# ATSAMA5D27 register map
Vendor: Microchip Technology Inc.; File version: 1.0
CPU: CA5 r0p1, little endian, no MPU, no FPU, 4 interrupt priority bits
Address unit: 32 bits
Registers are 32-bit, read-write, reset 0x0 unless marked. A register's access mark holds for its fields unless they carry their own. Offsets are from the block's base; [hi:lo] are bit positions; {n}, {i} and the like mark numbered series.

## SHDWC — Shutdown Controller
Base 0xF8048010
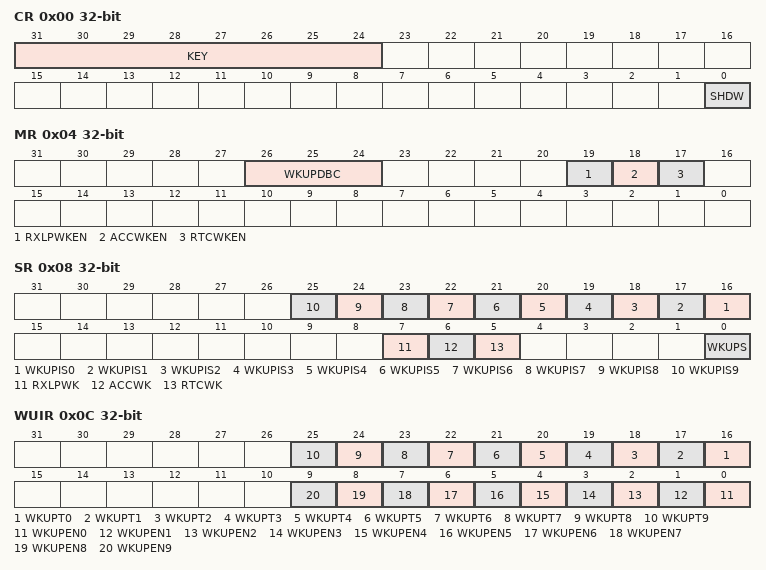
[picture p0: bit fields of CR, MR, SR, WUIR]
0x00 CR wo — Shutdown Control Register
  [31:24] KEY rw — Password
    165=PASSWD (Writing any other value in this field aborts the write operation.)
  [0] SHDW rw — Shutdown Command
0x04 MR — Shutdown Mode Register
  [26:24] WKUPDBC — Wake-up Inputs Debouncer Period
    0=IMMEDIATE (Immediate, no debouncing, detected active at least on one Slow Clock edge); 1=_3_SLCK (PIOBUx shall be in its active state for at least 3 SLCK periods); 2=_32_SLCK (PIOBUx shall be in its active state for at least 32 SLCK periods); 3=_512_SLCK (PIOBUx shall be in its active state for at least 512 SLCK periods); 4=_4096_SLCK (PIOBUx shall be in its active state for at least 4,096 SLCK periods); 5=_32768_SLCK (PIOBUx shall be in its active state for at least 32,768 SLCK periods)
  [19] RXLPWKEN — Debug Unit Wake-up Enable
  [18] ACCWKEN — Analog Comparator Controller Wake-up Enable
  [17] RTCWKEN — Real-time Clock Wake-up Enable
0x08 SR ro — Shutdown Status Register
  [n+16] WKUPIS{n} rw (n=0..9) — Wake-up {n} Input Status
    0=DISABLE (The corresponding wake-up input is disabled, or was inactive at the time the debouncer triggered a wake-up event.); 1=ENABLE (The corresponding wake-up input was active at the time the debouncer triggered a wake-up event.)
  [7] RXLPWK rw — Debug Unit Wake-up
  [6] ACCWK rw — Analog Comparator Controller Wake-up
  [5] RTCWK rw
  [0] WKUPS rw — PIOBU, WKUP Wake-up Status
    0=NO (No wake-up due to the assertion of the PIOBU, WKUP pins has occurred since the last read of SHDW_SR.); 1=PRESENT (At least one wake-up due to the assertion of the PIOBU, WKUP pins has occurred since the last read of SHDW_SR.)
0x0C WUIR — Shutdown Wake-up Inputs Register
  [n+16] WKUPT{n} (n=0..9) — Wake-up {n} Input Type
    0=LOW (A falling edge followed by a low level, for a period defined by WKUPDBC, on the corresponding wake-up input forces the wake-up of the core power supply.); 1=HIGH (A rising edge followed by a high level, for a period defined by WKUPDBC, on the corresponding wake-up input forces the wake-up of the core power supply.)
  [n] WKUPEN{n} (n=0..9) — Wake-up {n} Input Enable
    0=DISABLE (The corresponding wake-up input has no wake-up effect.); 1=ENABLE (The corresponding wake-up input forces the wake-up of the core power supply.)

## TDES — Triple Data Encryption Standard
Base 0xFC044000
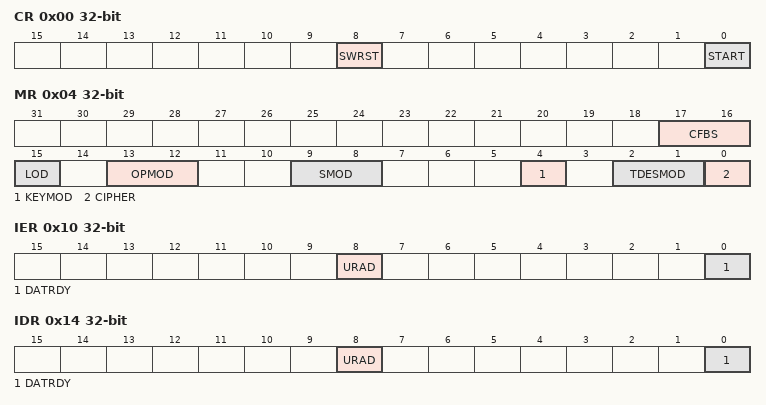
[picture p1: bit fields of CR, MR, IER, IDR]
0x00 CR wo — Control Register
  [8] SWRST rw — Software Reset
  [0] START rw — Start Processing
0x04 MR — Mode Register
  [17:16] CFBS — Cipher Feedback Data Size
    0=SIZE_64BIT (64-bit); 1=SIZE_32BIT (32-bit); 2=SIZE_16BIT (16-bit); 3=SIZE_8BIT (8-bit)
  [15] LOD — Last Output Data Mode
  [13:12] OPMOD — Operating Mode
    0=ECB (Electronic Code Book mode); 1=CBC (Cipher Block Chaining mode); 2=OFB (Output Feedback mode); 3=CFB (Cipher Feedback mode)
  [9:8] SMOD — Start Mode
    0=MANUAL_START (Manual Mode); 1=AUTO_START (Auto Mode); 2=IDATAR0_START (TDES_IDATAR0 accesses only Auto Mode)
  [4] KEYMOD — Key Mode
  [2:1] TDESMOD — ALGORITHM Mode
    0=SINGLE_DES (Single DES processing using Key 1 Registers); 1=TRIPLE_DES (Triple DES processing using Key 1, Key 2 and Key 3 Registers); 2=XTEA (XTEA processing using Key 1 and Key 2 Registers)
  [0] CIPHER — Processing Mode
    0=DECRYPT (Decrypts data.); 1=ENCRYPT (Encrypts data.)
0x10 IER wo — Interrupt Enable Register
  [8] URAD rw — Unspecified Register Access Detection Interrupt Enable
  [0] DATRDY rw — Data Ready Interrupt Enable
0x14 IDR wo — Interrupt Disable Register
  [8] URAD rw — Unspecified Register Access Detection Interrupt Disable
  [0] DATRDY rw — Data Ready Interrupt Disable
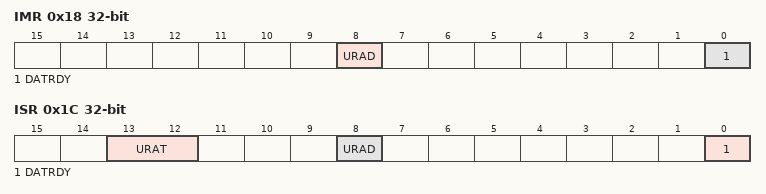
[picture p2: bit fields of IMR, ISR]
0x18 IMR ro — Interrupt Mask Register
  [8] URAD rw — Unspecified Register Access Detection Interrupt Mask
  [0] DATRDY rw — Data Ready Interrupt Mask
0x1C ISR ro — Interrupt Status Register
  [13:12] URAT rw — Unspecified Register Access (cleared by setting bit TDES_CR.SWRST)
    0=IDR_WR_PROCESSING (Input Data Register written during data processing when SMOD = 0x2 mode.); 1=ODR_RD_PROCESSING (Output Data Register read during data processing.); 2=MR_WR_PROCESSING (Mode Register written during data processing.); 3=WOR_RD_ACCESS (Write-only register read access.)
  [8] URAD rw — Unspecified Register Access Detection Status (cleared by setting bit TDES_CR.SWRST)
  [0] DATRDY rw — Data Ready (cleared by setting bit START or bit SWRST in TDES_CR or by reading TDES_ODATARx)
{0x18+8i} KEY{i}WR wo (i=1..3) — Key {i} Word Register
  [31:0] KEY{i}W rw — Key {i} Word
0x40 IDATAR wo — Input Data Register
  [31:0] IDATA rw — Input Data
0x50 ODATAR ro — Output Data Register
  [31:0] ODATA rw — Output Data
0x60 IVR wo — Initialization Vector Register
  [31:0] IV rw — Initialization Vector
0x70 XTEA_RNDR — XTEA Rounds Register
  [5:0] XTEA_RNDS — Number of Rounds
